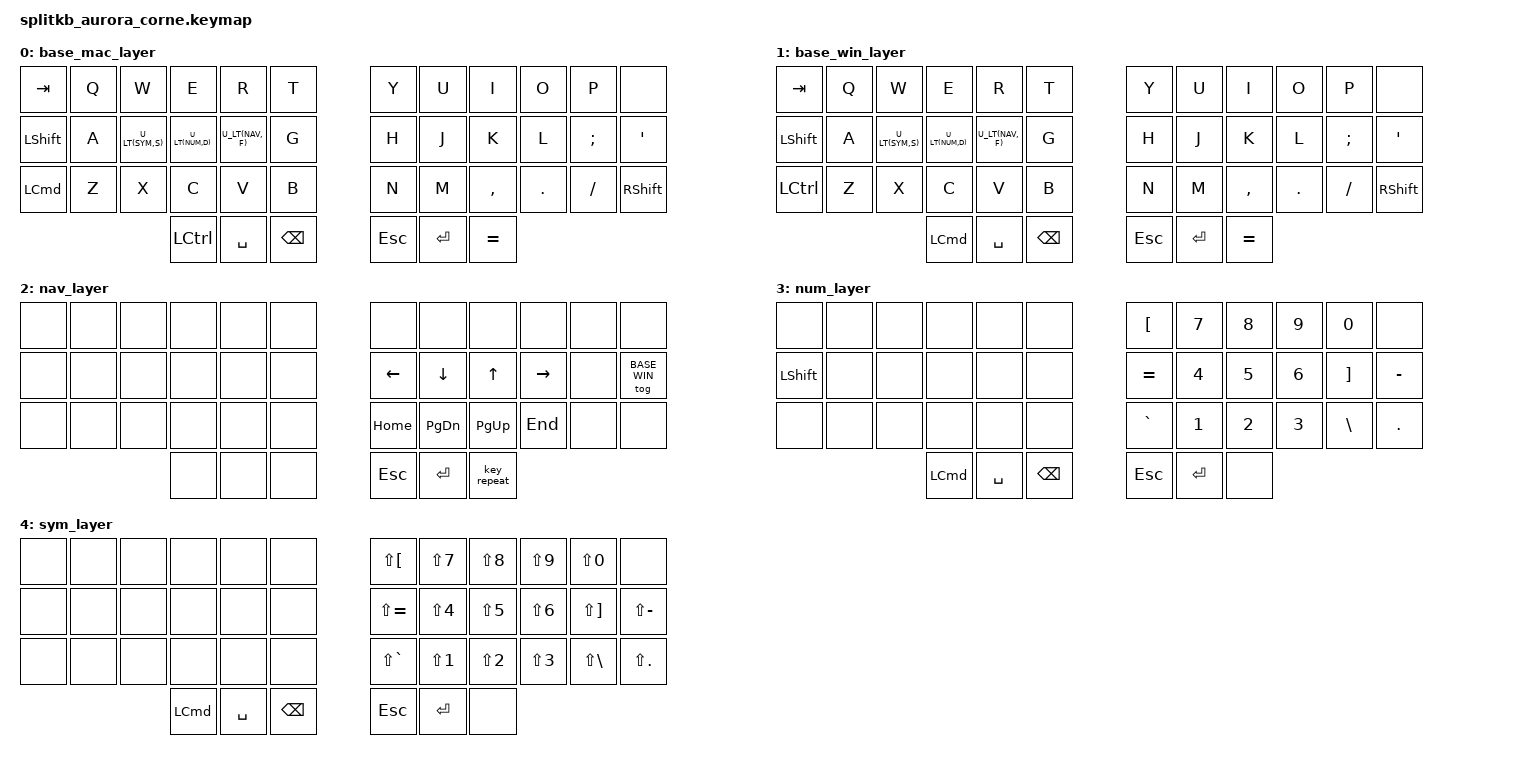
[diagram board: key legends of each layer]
/*
 * Copyright (c) 2020 The ZMK Contributors
 *
 * SPDX-License-Identifier: MIT
 */

#include <behaviors.dtsi>
#include <dt-bindings/zmk/keys.h>
#include <dt-bindings/zmk/bt.h>

#define BASE_MAC 0
#define BASE_WIN 1
#define NAV 2
#define NUM 3
#define SYM 4

#define U_MT(MOD, TAP) &mt MOD TAP
#define U_LT(LAYER, TAP) &lt LAYER TAP

&led_strip { chain-length = <27>; };

/ {
        keymap {
                compatible = "zmk,keymap";

                base_mac_layer {
                        bindings = <
   &kp TAB     &kp Q         &kp W         &kp E          &kp R          &kp T                &kp Y            &kp U      &kp I           &kp O   &kp P    &none 
   &kp LSHFT   &kp A         U_LT(SYM,S)   U_LT(NUM,D)    U_LT(NAV, F)   &kp G                &kp H            &kp J      &kp K           &kp L   &kp SEMI &kp SQT
   &kp LCMD    &kp Z         &kp X         &kp C          &kp V          &kp B                &kp N            &kp M      &kp COMMA       &kp DOT &kp FSLH &kp RSHFT
                                           &kp LCTRL       &kp SPACE      &kp BSPC            &kp ESC          &kp RET    &kp EQUAL
                        >;
                };

                base_win_layer {
                        bindings = <
   &kp TAB     &kp Q         &kp W         &kp E          &kp R          &kp T                &kp Y            &kp U      &kp I           &kp O   &kp P    &none 
   &kp LSHFT   &kp A         U_LT(SYM,S)   U_LT(NUM,D)    U_LT(NAV, F)   &kp G                &kp H            &kp J      &kp K           &kp L   &kp SEMI &kp SQT
   &kp LCTRL   &kp Z         &kp X         &kp C          &kp V          &kp B                &kp N            &kp M      &kp COMMA       &kp DOT &kp FSLH &kp RSHFT
                                           &kp LCMD       &kp SPACE      &kp BSPC             &kp ESC          &kp RET    &kp EQUAL
                        >;
                };


                nav_layer {
                        bindings = <
   &none    &none       &none       &none       &none       &none           &none             &none            &none        &none         &none         &none
   &none    &none       &none       &none       &none       &none           &kp LEFT          &kp DOWN         &kp UP       &kp RIGHT     &none         &tog BASE_WIN
   &none    &none       &none       &none       &none       &none           &kp HOME          &kp PG_DN        &kp PG_UP    &kp END       &none         &none
                                    &none       &none       &none           &kp ESC           &kp RET          &key_repeat
                        >;
                };

                num_layer {
                        bindings = <
   &none       &none      &none      &none      &none        &none          &kp LBKT          &kp N7           &kp N8        &kp N9       &kp N0        &none
   &kp LSHFT   &none      &none      &none      &none        &none          &kp EQUAL         &kp N4           &kp N5        &kp N6       &kp RBKT      &kp MINUS
   &none       &none      &none      &none      &none        &none          &kp GRAVE         &kp N1           &kp N2        &kp N3       &kp BSLH      &kp DOT
                                     &kp LCMD   &kp SPACE    &kp BSPC       &kp ESC           &kp RET          &none
                        >;
                };

                sym_layer {
                        bindings = <
   &none       &none      &none      &none      &none        &none          &kp LS(LBKT)      &kp LS(N7)       &kp LS(N8)    &kp LS(N9)   &kp LS(N0)    &none
   &none       &none      &none      &none      &none        &none          &kp LS(EQUAL)     &kp LS(N4)       &kp LS(N5)    &kp LS(N6)   &kp LS(RBKT)  &kp LS(MINUS)
   &none       &none      &none      &none      &none        &none          &kp LS(GRAVE)     &kp LS(N1)       &kp LS(N2)    &kp LS(N3)   &kp LS(BSLH)  &kp LS(DOT)
                                     &kp LCMD   &kp SPACE    &kp BSPC       &kp ESC           &kp RET          &none
                        >;
                };

        };
};
